# CM41x_M4 register map
Vendor: Analog Devices; Series: CM41x_M4; File version: 1p0
CPU: CM4 r0p1, little endian, MPU, FPU, 4 interrupt priority bits
Registers are 32-bit, read-write, reset 0x0 unless marked. A register's access mark holds for its fields unless they carry their own. Offsets are from the block's base; [hi:lo] are bit positions.

## WDOG0 — Watchdog Timer Unit
Base 0x41005000
Same registers: WDOG1 0x40011000
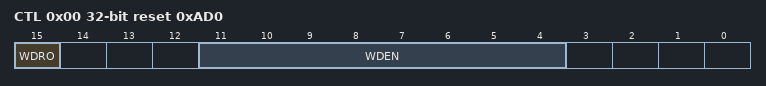
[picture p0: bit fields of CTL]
0x00 CTL reset 0xAD0 — Control Register
  [15] WDRO — Watch Dog Rollover
  [11:4] WDEN — Watch Dog Enable
0x04 CNT — Count Register
  [31:0] VALUE range 0x00000000..0xFFFFFFFF — Count Value
0x08 STAT — Watchdog Timer Status Register
  [31:0] VALUE range 0x00000000..0xFFFFFFFF — Current Count Value (Status)

## RCU0 — Reset Control Unit
Base 0x40012000
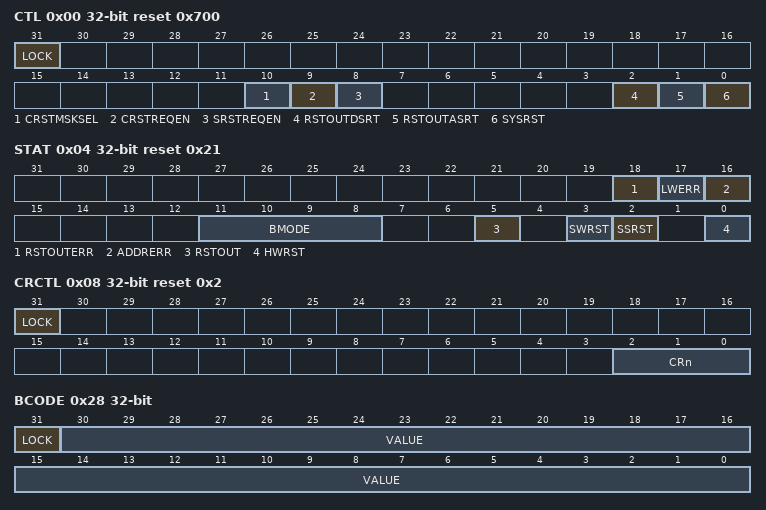
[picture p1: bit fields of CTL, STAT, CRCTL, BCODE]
0x00 CTL reset 0x700 — Control Register
  [31] LOCK
  [10] CRSTMSKSEL range 0x00000000..0x00000001 — Core Reset System Reset Mask Select
  [9] CRSTREQEN — Core Reset Request Enabled
  [8] SRSTREQEN — System Reset Request Enabled
  [2] RSTOUTDSRT — Reset Out Deassert
  [1] RSTOUTASRT — Reset Out Assert
  [0] SYSRST — System Reset
0x04 STAT reset 0x21 — Status Register
  [18] RSTOUTERR — Reset Out Error
  [17] LWERR — Lock Write Error
  [16] ADDRERR — Address Error
  [11:8] BMODE ro — Boot Mode
  [5] RSTOUT ro — Reset Out Status
  [3] SWRST — Software Reset
  [2] SSRST — System Source Reset
  [0] HWRST — Hardware Reset
0x08 CRCTL reset 0x2 — Core Reset Outputs Control Register
  [31] LOCK
  [2:0] CRn — Core Reset Outputs
0x0C CRSTAT reset 0x7 — Core Reset Outputs Status Register
  [2:0] CRn — Core Reset Outputs
0x18 SRRQSTAT — System Reset Request Status Register
  [7:0] SRRQ range 0x00000000..0x000000FF — System Reset Triggered by System Reset Request [n]
0x28 BCODE — Boot Code Register
  [31] LOCK, [30:0] VALUE range 0x00000000..0x7FFFFFFF
0x6C MSG — Message Register
  [31:0] VALUE range 0x00000000..0xFFFFFFFF — Module DV value
0x70 MSG_SET — Message Set Bits Register
  [31:0] SET range 0x00000000..0xFFFFFFFF — Set Message Bits
0x74 MSG_CLR — Message Clear Bits Register
  [31:0] CLR range 0x00000000..0xFFFFFFFF — Clear MSG Register Bits

## DPM0 — Dynamic Power Management
Base 0x40013000
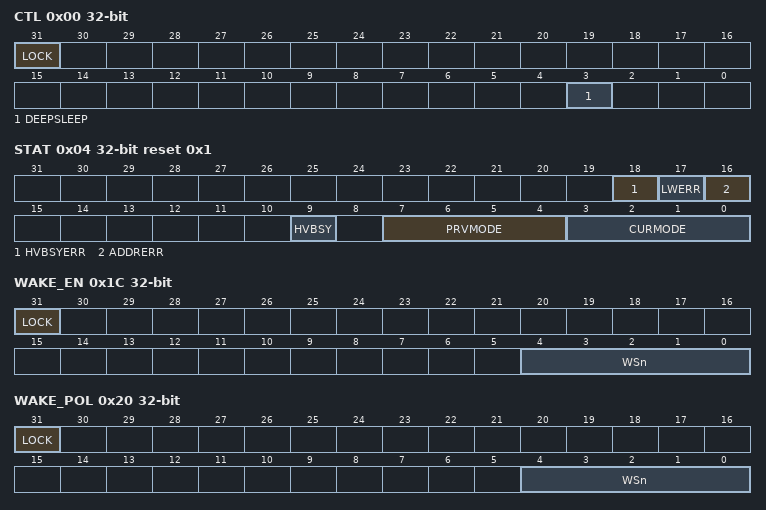
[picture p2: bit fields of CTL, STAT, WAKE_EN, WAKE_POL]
0x00 CTL — Control Register
  [31] LOCK, [3] DEEPSLEEP
0x04 STAT reset 0x1 — Status Register
  [18] HVBSYERR — HV Busy Error
  [17] LWERR — Lock Write Error
  [16] ADDRERR — Address Error
  [9] HVBSY ro — HV Busy
  [7:4] PRVMODE ro — Previous Mode
  [3:0] CURMODE ro — Current Mode
0x1C WAKE_EN — Wakeup Enable Register
  [31] LOCK
  [4:0] WSn range 0x00000000..0x0000001F — Wakeup Source n Enable
0x20 WAKE_POL — Wakeup Polarity Register
  [31] LOCK
  [4:0] WSn — Wakeup Source n Polarity
0x24 WAKE_STAT — Wakeup Status Register
  [4:0] WSn — Wakeup Source n Status
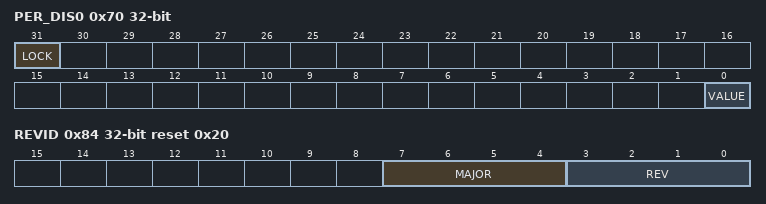
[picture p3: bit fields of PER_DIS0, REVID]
0x70 PER_DIS0 — Peripherals Disable Register 0
  [31] LOCK range 0x00000000..0x00000001 — Lock Bit
  [0] VALUE range 0x00000000..0x00000001 — Peripheral Disable
0x84 REVID reset 0x20 — Revision ID
  [7:4] MAJOR ro — Major Version ID
  [3:0] REV ro — Incremental Version ID

## CGU0 — Clock Generation Unit
Base 0x40014000
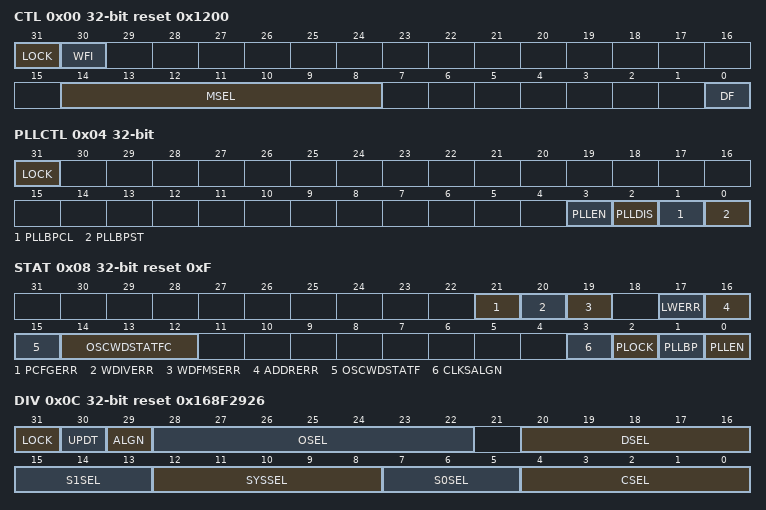
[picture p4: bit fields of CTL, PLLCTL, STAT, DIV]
0x00 CTL reset 0x1200 — Control Register
  [31] LOCK
  [30] WFI — Wait For Idle
  [14:8] MSEL — Multiplier Select
  [0] DF — Divide Frequency
0x04 PLLCTL — PLL Control Register
  [31] LOCK
  [3] PLLEN — PLL Enable
  [2] PLLDIS — PLL Disable
  [1] PLLBPCL — PLL Bypass Clear
  [0] PLLBPST — PLL Bypass Set
0x08 STAT reset 0xF — Status Register
  [21] PCFGERR — PLL Configuration Error
  [20] WDIVERR — Write to DIV Error
  [19] WDFMSERR — Write to DF or MSEL Error
  [17] LWERR — Lock Write Error
  [16] ADDRERR — Address Error
  [15] OSCWDSTATF ro — Oscillator Watchdog Status Fault
  [14:12] OSCWDSTATFC ro — Oscillator Watchdog Status Fault Code
  [3] CLKSALGN ro — Clock Alignment
  [2] PLOCK ro — PLL Lock
  [1] PLLBP ro — PLL Bypass
  [0] PLLEN ro — PLL Enable
0x0C DIV reset 0x168F2926 — Clocks Divisor Register
  [31] LOCK
  [30] UPDT — Update Clock Divisors
  [29] ALGN — Align
  [28:22] OSEL — OCLK Divisor
  [20:16] DSEL — DCLK Divisor
  [15:13] S1SEL — Short Clocks Alignment Time
  [12:8] SYSSEL — SYSCLK Divisor
  [7:5] S0SEL — SCLK 0 Divisor
  [4:0] CSEL — CCLK Divisor
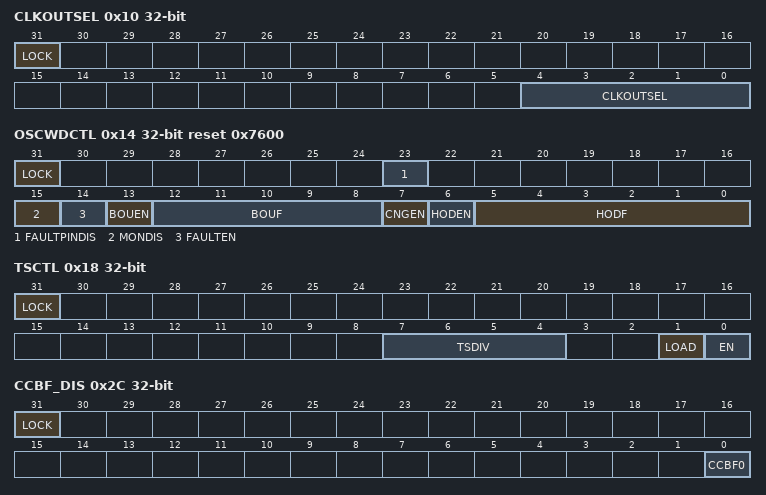
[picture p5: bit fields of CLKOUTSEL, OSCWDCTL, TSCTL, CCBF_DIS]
0x10 CLKOUTSEL — CLKOUT Select Register
  [31] LOCK
  [4:0] CLKOUTSEL — CLKOUT Select
0x14 OSCWDCTL reset 0x7600 — Oscillator Watchdog Register
  [31] LOCK range 0x00000000..0x00000001
  [23] FAULTPINDIS range 0x00000000..0x00000001 — Fault Pin disabled
  [15] MONDIS range 0x00000000..0x00000001 — Oscillator Watchdog Monitor functions disabled
  [14] FAULTEN range 0x00000000..0x00000001 — Fault enabled
  [13] BOUEN range 0x00000000..0x00000001 — Bad Oscillator Upper Frequency limit detection enabled
  [12:8] BOUF range 0x00000000..0x0000001F — Bad Oscillator Upper Frequency limit
  [7] CNGEN range 0x00000000..0x00000001 — Clock not Good enabled
  [6] HODEN range 0x00000000..0x00000001 — Harmonic Oscillation Detection enabled
  [5:0] HODF range 0x00000000..0x0000003F — Watchdog lower frequency limit
0x18 TSCTL — Time Stamp Control Register
  [31] LOCK
  [7:4] TSDIV — Counter's Clock Divider
  [1] LOAD — Load Counter
  [0] EN — Counter Enable
0x1C TSVALUE0 — Time Stamp Counter Initial 32 LSB Value Register
  [31:0] VALUE range 0x00000000..0xFFFFFFFF — Counter's 32 LSB Initial Value
0x20 TSVALUE1 — Time Stamp Counter Initial MSB Value Register
  [31:0] VALUE range 0x00000000..0xFFFFFFFF — Counter's Initial 32 MSB Value
0x24 TSCOUNT0 — Time Stamp Counter 32 LSB Register
  [31:0] VALUE ro — TSCOUNT0 Value
0x28 TSCOUNT1 — Time Stamp Counter 32 MSB Register
  [31:0] VALUE ro — Timestamp Counter 32 MSB
0x2C CCBF_DIS — Core Clock Buffer Disable Register
  [31] LOCK
  [0] CCBF0 — Core Clock Buffer 0
0x30 CCBF_STAT — Core Clock Buffer Status Register
  [0] CCBF0 ro — Core Clock Buffer 0
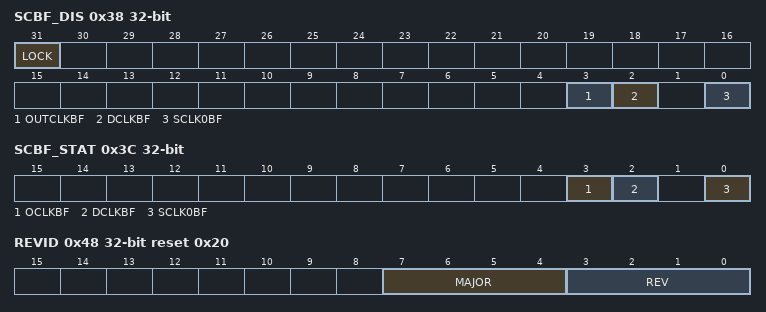
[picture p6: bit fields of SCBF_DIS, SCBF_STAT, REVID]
0x38 SCBF_DIS — System Clock Buffer Disable Register
  [31] LOCK
  [3] OUTCLKBF — OCLK Buffer
  [2] DCLKBF — DCLK Buffer
  [0] SCLK0BF — SCLK0 Buffer
0x3C SCBF_STAT — System Clock Buffer Status Register
  [3] OCLKBF ro — OCLK Buffer
  [2] DCLKBF ro — DCLK1 Buffer
  [0] SCLK0BF ro — SCLK0 Buffer
0x48 REVID reset 0x20 — Revision ID Register
  [7:4] MAJOR ro — Major Version
  [3:0] REV ro — Incremental Version ID
